AUTOSAR XML (schema 4-0-3)
standard types defined: Boolean, UInt32, UInt8
package /AUTOSAR_Platform/DataConstrs
  range DC_Boolean: raw 0..1
  range DC_UInt8: raw 0..255
package /PATAC/MSM/ComponentTypes
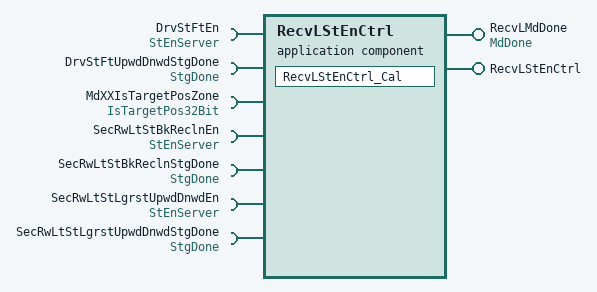
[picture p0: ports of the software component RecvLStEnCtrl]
  application sw component type RecvLStEnCtrl
    provide port RecvLMdDone: nonqueued-sender-com-spec{data-element=MdDone/Val, init-value=0}, provided-interface=MdDone
    provide port RecvLStEnCtrl: server-com-spec{operation=Cal, queue-length=1}, provided-interface=RecvLStEnCtrl
    7 x require port:
      DrvStFtEn: required-com-specs=[Clear, Get, Set], required-interface=StEnServer
      DrvStFtUpwdDnwdStgDone: nonqueued-receiver-com-spec{data-element=StgDone/Val, filter=data-filter-type=ALWAYS, init-value=0}, required-interface=StgDone
      MdXXIsTargetPosZone: nonqueued-receiver-com-spec{data-element=IsTargetPos32Bit/Val, filter=data-filter-type=ALWAYS, init-value=0}, required-interface=IsTargetPos32Bit
      SecRwLtStBkReclnEn: required-com-specs=[Clear, Get, Set], required-interface=StEnServer
      SecRwLtStBkReclnStgDone: nonqueued-receiver-com-spec{data-element=StgDone/Val, filter=data-filter-type=ALWAYS, init-value=0}, required-interface=StgDone
      SecRwLtStLgrstUpwdDnwdEn: required-com-specs=[Clear, Get, Set], required-interface=StEnServer
      SecRwLtStLgrstUpwdDnwdStgDone: nonqueued-receiver-com-spec{data-element=StgDone/Val, filter=data-filter-type=ALWAYS, init-value=0}, required-interface=StgDone
    behavior RecvLStEnCtrl_InternalBehavior
      operation invoked event OIT_RecvLStEnCtrl_Cal_RecvLStEnCtrl_Cal: start-on-event=RecvLStEnCtrl_Cal, operation=RecvLStEnCtrl.Cal
      runnable RecvLStEnCtrl_Cal
        data-receive-point-by-arguments:
          4 x access:
            REC_DrvStFtUpwdDnwdStgDone_Val: accessed-variable=DrvStFtUpwdDnwdStgDone.Val
            REC_MdXXIsTargetPosZone_Val: accessed-variable=MdXXIsTargetPosZone.Val
            REC_SecRwLtStBkReclnStgDone_Val: accessed-variable=SecRwLtStBkReclnStgDone.Val
            REC_SecRwLtStLgrstUpwdDnwdStgDone_Val: accessed-variable=SecRwLtStLgrstUpwdDnwdStgDone.Val
        data-send-points:
          access SEND_RecvLMdDone_Val: accessed-variable=RecvLMdDone.Val
        6 x sync call, all with timeout=0:
          SC_DrvStFtEn_Clear: operation=DrvStFtEn.Clear
          SC_DrvStFtEn_Set: operation=DrvStFtEn.Set
          SC_SecRwLtStBkReclnEn_Clear: operation=SecRwLtStBkReclnEn.Clear
          SC_SecRwLtStBkReclnEn_Set: operation=SecRwLtStBkReclnEn.Set
          SC_SecRwLtStLgrstUpwdDnwdEn_Clear: operation=SecRwLtStLgrstUpwdDnwdEn.Clear
          SC_SecRwLtStLgrstUpwdDnwdEn_Set: operation=SecRwLtStLgrstUpwdDnwdEn.Set
  swc implementation RecvLStEnCtrl_Implementation: behavior=RecvLStEnCtrl_InternalBehavior
    code-descriptors:
      code Default: artifact-descriptors=autosar-engineering-object={short-label=Default, category=SWSRC}
package /PATAC/MSM/ModeAdjust/PortInterface
  client server interface RecvLStEnCtrl
    operation Cal
  client server interface StEnServer
    operation Clear
      arg data: type=UInt8, direction=IN, server-argument-impl-policy=USE-ARGUMENT-TYPE
    operation Get
      arg data: type=UInt32, direction=OUT, server-argument-impl-policy=USE-ARGUMENT-TYPE
    operation Set
      arg data: type=UInt8, direction=IN, server-argument-impl-policy=USE-ARGUMENT-TYPE
  sender receiver interface IsTargetPos32Bit: invalidation-policy{data-element=IsTargetPos32Bit/Val, handle-invalid=DONT-INVALIDATE}
    data Val: type=UInt32
  sender receiver interface MdDone: invalidation-policy{data-element=MdDone/Val, handle-invalid=DONT-INVALIDATE}
    data Val: type=UInt8
  sender receiver interface StgDone: invalidation-policy{data-element=StgDone/Val, handle-invalid=DONT-INVALIDATE}
    data Val: type=Boolean
